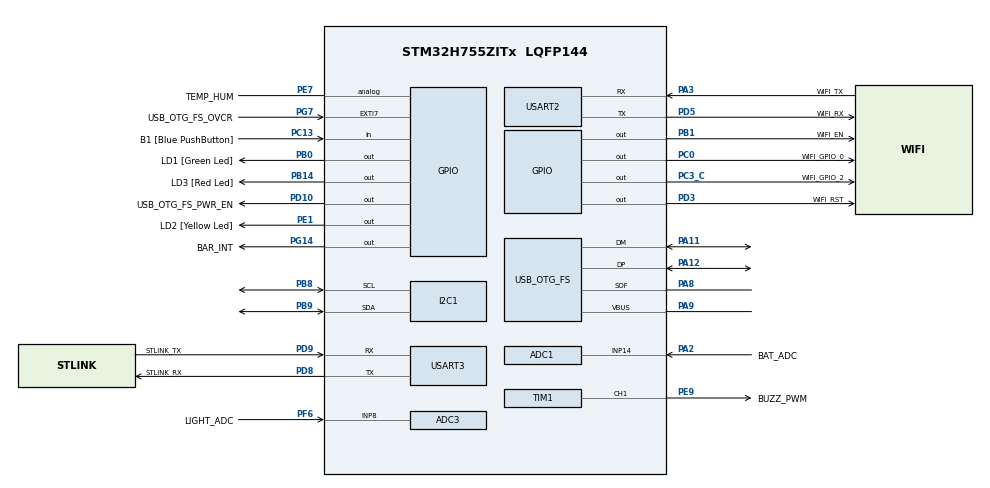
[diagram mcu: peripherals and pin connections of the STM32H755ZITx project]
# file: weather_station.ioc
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ADC1.Channel-1\#ChannelRegularConversion=ADC_CHANNEL_14
ADC1.NbrOfConversionFlag=1
ADC1.OffsetNumber-1\#ChannelRegularConversion=ADC_OFFSET_NONE
ADC1.OffsetSignedSaturation-1\#ChannelRegularConversion=DISABLE
ADC1.Rank-1\#ChannelRegularConversion=1
ADC1.SamplingTime-1\#ChannelRegularConversion=ADC_SAMPLETIME_8CYCLES_5
ADC1.master=1
ADC3.Channel-0\#ChannelRegularConversion=ADC_CHANNEL_8
ADC3.ContinuousConvMode=DISABLE
ADC3.NbrOfConversion=1
ADC3.NbrOfConversionFlag=1
ADC3.OffsetNumber-0\#ChannelRegularConversion=ADC_OFFSET_NONE
ADC3.OffsetSignedSaturation-0\#ChannelRegularConversion=DISABLE
ADC3.Rank-0\#ChannelRegularConversion=1
ADC3.SamplingTime-0\#ChannelRegularConversion=ADC_SAMPLETIME_8CYCLES_5
ARM.CMSIS.5.7.0.CMSISJjCORE=true
ARM.CMSIS.5.7.0.CMSISOoDriverJjI2CJjCustom=true
ARM.CMSIS.5.7.0.CMSISOoDriverJjUSARTJjCustom=true
ARM.CMSIS.5.7.0.CMSISOoDriverJjWiFiJjCustom=true
CortexM4.IPs=FATFS_M4\:I,FREERTOS_M4\:I,IWDG2\:I,RCC,WWDG2\:I,DMA,BDMA,MDMA,NVIC2\:I,USART3,DEBUG,USB_DEVICE_M4\:I,USB_HOST_M4\:I,PDM2PCM_M4\:I,PWR,RESMGR_UTILITY,SYS_M4\:I,CORTEX_M4\:I,OPENAMP_M4\:I,VREFBUF
CortexM7.IPs=FATFS_M7\:I,FREERTOS_M7\:I,IWDG1\:I,RCC\:I,WWDG1\:I,DMA\:I,BDMA\:I,MDMA\:I,NVIC1\:I,USART3\:I,USB_OTG_FS\:I,SYS\:I,CORTEX_M7\:I,DEBUG\:I,USB_DEVICE_M7\:I,USB_HOST_M7\:I,PDM2PCM_M7\:I,PWR\:I,RESMGR_UTILITY\:I,OPENAMP_M7\:I,VREFBUF\:I,ADC3\:I,TIM1\:I,USART2\:I,STMicroelectronics.X-CUBE-ALGOBUILD.1.1.0\:I,I2C1\:I,TIM6\:I,ADC1\:I
CortexM7.Pins=PC13,PC0,PC3_C,PB0,PB1,PE7,PB14,PD10,PD3,PG14,PE1
I2C1.Timing=0x307075B1
Mcu.Family=STM32H7
Mcu.Name=STM32H755ZITx
Mcu.Package=LQFP144
NVIC1.PriorityGroup=NVIC_PRIORITYGROUP_4
NVIC2.PriorityGroup=NVIC_PRIORITYGROUP_4
PA11.Mode=Device_Only
PA11.PinAttribute=CortexM7
PA11.Signal=USB_OTG_FS_DM
PA12.Mode=Device_Only
PA12.PinAttribute=CortexM7
PA12.Signal=USB_OTG_FS_DP
PA2.GPIO_Label=BAT_ADC
PA2.PinAttribute=CortexM7
PA2.Signal=ADCx_INP14
PA3.GPIO_Label=WIFI_TX
PA3.Mode=Asynchronous
PA3.PinAttribute=CortexM7
PA3.Signal=USART2_RX
PA8.Mode=Activate_SOF_FS
PA8.PinAttribute=CortexM7
PA8.Signal=USB_OTG_FS_SOF
PA9.Mode=Activate_VBUS
PA9.PinAttribute=CortexM7
PA9.Signal=USB_OTG_FS_VBUS
PB0.GPIO_Label=LD1 [Green Led]
PB0.PinAttribute=CortexM7
PB0.Signal=GPIO_Output
PB1.GPIO_Label=WIFI_EN
PB1.GPIO_PuPd=GPIO_PULLUP
PB1.PinAttribute=CortexM7
PB1.Signal=GPIO_Output
PB14.GPIO_Label=LD3 [Red Led]
PB14.PinAttribute=CortexM7
PB14.Signal=GPIO_Output
PB8.Mode=I2C
PB8.PinAttribute=CortexM7
PB8.Signal=I2C1_SCL
PB9.Mode=I2C
PB9.PinAttribute=CortexM7
PB9.Signal=I2C1_SDA
PC0.GPIO_Label=WIFI_GPIO_0
PC0.PinAttribute=CortexM7
PC0.Signal=GPIO_Output
PC13.GPIO_Label=B1 [Blue PushButton]
PC13.PinAttribute=CortexM7
PC13.Signal=GPIO_Input
PC14-OSC32_IN\ (OSC32_IN).PinAttribute=CortexM7
PC14-OSC32_IN\ (OSC32_IN).Signal=RCC_OSC32_IN
PC15-OSC32_OUT\ (OSC32_OUT).PinAttribute=CortexM7
PC15-OSC32_OUT\ (OSC32_OUT).Signal=RCC_OSC32_OUT
PC3_C.GPIO_Label=WIFI_GPIO_2
PC3_C.PinAttribute=CortexM7
PC3_C.Signal=GPIO_Output
PD10.GPIO_Label=USB_OTG_FS_PWR_EN
PD10.PinAttribute=CortexM7
PD10.Signal=GPIO_Output
PD3.GPIO_Label=WIFI_RST
PD3.PinAttribute=CortexM7
PD3.Signal=GPIO_Output
PD5.GPIO_Label=WIFI_RX
PD5.Mode=Asynchronous
PD5.PinAttribute=CortexM7
PD5.Signal=USART2_TX
PD8.GPIO_Label=STLINK_RX
PD8.Mode=Asynchronous
PD8.PinAttribute=CortexM7
PD8.Signal=USART3_TX
PD9.GPIO_Label=STLINK_TX
PD9.Mode=Asynchronous
PD9.PinAttribute=CortexM7
PD9.Signal=USART3_RX
PE1.GPIO_Label=LD2 [Yellow Led]
PE1.PinAttribute=CortexM7
PE1.Signal=GPIO_Output
PE7.GPIO_Label=TEMP_HUM
PE7.PinAttribute=CortexM7
PE7.Signal=GPIO_Analog
PE9.GPIO_Label=BUZZ_PWM
PE9.PinAttribute=CortexM7
PE9.Signal=S_TIM1_CH1
PF6.GPIO_Label=LIGHT_ADC
PF6.Mode=IN8-Single-Ended
PF6.PinAttribute=CortexM7
PF6.Signal=ADC3_INP8
PG14.GPIO_Label=BAR_INT
PG14.PinAttribute=CortexM7
PG14.Signal=GPIO_Output
PG7.GPIO_Label=USB_OTG_FS_OVCR
PG7.PinAttribute=Free
PG7.Signal=GPXTI7
PH0-OSC_IN\ (PH0).Mode=HSE-External-Oscillator
PH0-OSC_IN\ (PH0).PinAttribute=CortexM7
PH0-OSC_IN\ (PH0).Signal=RCC_OSC_IN
PH1-OSC_OUT\ (PH1).Mode=HSE-External-Oscillator
PH1-OSC_OUT\ (PH1).PinAttribute=CortexM7
PH1-OSC_OUT\ (PH1).Signal=RCC_OSC_OUT
ProjectManager.HeapSize=0x200
ProjectManager.StackSize=0x400
ProjectManager.TargetToolchain=STM32CubeIDE
RCC.ADCFreq_Value=150000000
RCC.APB1Freq_Value=120000000
RCC.APB2Freq_Value=120000000
RCC.APB3Freq_Value=120000000
RCC.APB4Freq_Value=120000000
RCC.CortexFreq_Value=480000000
RCC.D1PPRE=RCC_APB3_DIV2
RCC.D2PPRE1=RCC_APB1_DIV2
RCC.D2PPRE2=RCC_APB2_DIV2
RCC.D3PPRE=RCC_APB4_DIV2
RCC.DIVM1=1
RCC.DIVM2=1
RCC.DIVN1=120
RCC.DIVN2=18
RCC.DIVP2=1
RCC.DIVQ1=20
RCC.HCLKFreq_Value=240000000
RCC.HPRE=RCC_HCLK_DIV2
RCC.HSE_VALUE=8000000
RCC.PLL2FRACN=6144
RCC.PLL3FRACN=0
RCC.PLLFRACN=0
RCC.SYSCLKFreq_VALUE=480000000
RCC.SYSCLKSource=RCC_SYSCLKSOURCE_PLLCLK
RCC.SupplySource=PWR_DIRECT_SMPS_SUPPLY
RCC.USBFreq_Value=48000000
SH.ADCx_INP14.0=ADC1_INP14,IN14-Single-Ended
SH.S_TIM1_CH1.0=TIM1_CH1,PWM Generation1 CH1
STMicroelectronics.X-CUBE-ALGOBUILD.1.1.0.LibraryCcDSPOoLibraryJjDSPOoLibrary=true
TIM1.Channel-PWM\ Generation1\ CH1=TIM_CHANNEL_1
TIM1.Period=1000-1
TIM1.Prescaler=240-1
TIM6.Period=0xffff
TIM6.Prescaler=239
USART2.VirtualMode-Asynchronous=VM_ASYNC
USART3.VirtualMode-Asynchronous=VM_ASYNC
USB_OTG_FS.VirtualMode=Device_Only
VP_STMicroelectronics.X-CUBE-ALGOBUILD_VS_DSPOoLibraryJjLibrary_1.1.0.Mode=DSPOoLibraryJjLibrary
VP_SYS_M4_VS_Systick.Mode=SysTick
VP_TIM1_VS_ClockSourceINT.Mode=Internal
VP_TIM6_VS_ClockSourceINT.Mode=Enable_Timer
board=NUCLEO-H755ZI-Q

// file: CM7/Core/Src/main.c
/* USER CODE BEGIN Header */
/**
  ******************************************************************************
  * @file           : main.c
  * @brief          : Main program body
  ******************************************************************************
  * @attention
  *
  * <h2><center>&copy; Copyright (c) 2020 STMicroelectronics.
  * All rights reserved.</center></h2>
  *
  * This software component is licensed by ST under BSD 3-Clause license,
  * the "License"; You may not use this file except in compliance with the
  * License. You may obtain a copy of the License at:
  *                        opensource.org/licenses/BSD-3-Clause
  *
  ******************************************************************************
  */
/* USER CODE END Header */
#include "main.h"
#include "adc.h"
#include "i2c.h"
#include "tim.h"
#include "usart.h"
#include "usb_otg.h"
#include "gpio.h"

/* USER CODE BEGIN PD */
#define HSEM_ID_0 (0U) /* HW semaphore 0*/
/* USER CODE END PD */

void SystemClock_Config(void);

int main(void)
{

/* USER CODE BEGIN Boot_Mode_Sequence_0 */
  int32_t timeout;
/* USER CODE END Boot_Mode_Sequence_0 */

/* USER CODE BEGIN Boot_Mode_Sequence_1 */
  /* Wait until CPU2 boots and enters in stop mode or timeout*/
  timeout = 0xFFFF;
  while((__HAL_RCC_GET_FLAG(RCC_FLAG_D2CKRDY) != RESET) && (timeout-- > 0));
  if ( timeout < 0 )
  {
  Error_Handler();
  }
/* USER CODE END Boot_Mode_Sequence_1 */
  /* MCU Configuration--------------------------------------------------------*/

  /* Reset of all peripherals, Initializes the Flash interface and the Systick. */
  HAL_Init();

  /* USER CODE BEGIN Init */
  char test[28];
  double temp_hum_sens[2] = {0, 0}, light_level = 0;
  /* USER CODE END Init */

  /* Configure the system clock */
  SystemClock_Config();
/* USER CODE BEGIN Boot_Mode_Sequence_2 */
/* When system initialization is finished, Cortex-M7 will release Cortex-M4 by means of
HSEM notification */
/*HW semaphore Clock enable*/
__HAL_RCC_HSEM_CLK_ENABLE();
/*Take HSEM */
HAL_HSEM_FastTake(HSEM_ID_0);
/*Release HSEM in order to notify the CPU2(CM4)*/
HAL_HSEM_Release(HSEM_ID_0,0);
/* wait until CPU2 wakes up from stop mode */
timeout = 0xFFFF;
while((__HAL_RCC_GET_FLAG(RCC_FLAG_D2CKRDY) == RESET) && (timeout-- > 0));
if ( timeout < 0 )
{
Error_Handler();
}
/* USER CODE END Boot_Mode_Sequence_2 */

  /* Initialize all configured peripherals */
  MX_GPIO_Init();
  MX_USART3_UART_Init();
  MX_USB_OTG_FS_PCD_Init();
  MX_ADC3_Init();
  MX_TIM1_Init();
  MX_USART2_UART_Init();
  MX_I2C1_Init();
  MX_TIM6_Init();
  MX_ADC1_Init();

  /* Infinite loop */
  /* USER CODE BEGIN WHILE */
  while (1){
	  light_level = analog_sensor(&hadc3, 800);
	  battery_level(&hadc1, test, 3.7);
	  dht11_run(htim6, TEMP_HUM_GPIO_Port, TEMP_HUM_Pin, temp_hum_sens);

    /* USER CODE END WHILE */

  }
}

void SystemClock_Config(void)
{
  RCC_OscInitTypeDef RCC_OscInitStruct = {0};
  RCC_ClkInitTypeDef RCC_ClkInitStruct = {0};
  RCC_PeriphCLKInitTypeDef PeriphClkInitStruct = {0};

  /** Supply configuration update enable
  */
  HAL_PWREx_ConfigSupply(PWR_DIRECT_SMPS_SUPPLY);
  /** Configure the main internal regulator output voltage
  */
  __HAL_PWR_VOLTAGESCALING_CONFIG(PWR_REGULATOR_VOLTAGE_SCALE0);

  while(!__HAL_PWR_GET_FLAG(PWR_FLAG_VOSRDY)) {}
  /** Macro to configure the PLL clock source
  */
  __HAL_RCC_PLL_PLLSOURCE_CONFIG(RCC_PLLSOURCE_HSE);
  /** Initializes the RCC Oscillators according to the specified parameters
  * in the RCC_OscInitTypeDef structure.
  */
  RCC_OscInitStruct.OscillatorType = RCC_OSCILLATORTYPE_HSE;
  RCC_OscInitStruct.HSEState = RCC_HSE_ON;
  RCC_OscInitStruct.PLL.PLLState = RCC_PLL_ON;
  RCC_OscInitStruct.PLL.PLLSource = RCC_PLLSOURCE_HSE;
  RCC_OscInitStruct.PLL.PLLM = 1;
  RCC_OscInitStruct.PLL.PLLN = 120;
  RCC_OscInitStruct.PLL.PLLP = 2;
  RCC_OscInitStruct.PLL.PLLQ = 20;
  RCC_OscInitStruct.PLL.PLLR = 2;
  RCC_OscInitStruct.PLL.PLLRGE = RCC_PLL1VCIRANGE_3;
  RCC_OscInitStruct.PLL.PLLVCOSEL = RCC_PLL1VCOWIDE;
  RCC_OscInitStruct.PLL.PLLFRACN = 0;
  if (HAL_RCC_OscConfig(&RCC_OscInitStruct) != HAL_OK)
  {
    Error_Handler();
  }
  /** Initializes the CPU, AHB and APB buses clocks
  */
  RCC_ClkInitStruct.ClockType = RCC_CLOCKTYPE_HCLK|RCC_CLOCKTYPE_SYSCLK
                              |RCC_CLOCKTYPE_PCLK1|RCC_CLOCKTYPE_PCLK2
                              |RCC_CLOCKTYPE_D3PCLK1|RCC_CLOCKTYPE_D1PCLK1;
  RCC_ClkInitStruct.SYSCLKSource = RCC_SYSCLKSOURCE_PLLCLK;
  RCC_ClkInitStruct.SYSCLKDivider = RCC_SYSCLK_DIV1;
  RCC_ClkInitStruct.AHBCLKDivider = RCC_HCLK_DIV2;
  RCC_ClkInitStruct.APB3CLKDivider = RCC_APB3_DIV2;
  RCC_ClkInitStruct.APB1CLKDivider = RCC_APB1_DIV2;
  RCC_ClkInitStruct.APB2CLKDivider = RCC_APB2_DIV2;
  RCC_ClkInitStruct.APB4CLKDivider = RCC_APB4_DIV2;

  if (HAL_RCC_ClockConfig(&RCC_ClkInitStruct, FLASH_LATENCY_4) != HAL_OK)
  {
    Error_Handler();
  }
  PeriphClkInitStruct.PeriphClockSelection = RCC_PERIPHCLK_USART3|RCC_PERIPHCLK_USART2
                              |RCC_PERIPHCLK_ADC|RCC_PERIPHCLK_I2C1
                              |RCC_PERIPHCLK_USB;
  PeriphClkInitStruct.PLL2.PLL2M = 1;
  PeriphClkInitStruct.PLL2.PLL2N = 18;
  PeriphClkInitStruct.PLL2.PLL2P = 1;
  PeriphClkInitStruct.PLL2.PLL2Q = 2;
  PeriphClkInitStruct.PLL2.PLL2R = 2;
  PeriphClkInitStruct.PLL2.PLL2RGE = RCC_PLL2VCIRANGE_3;
  PeriphClkInitStruct.PLL2.PLL2VCOSEL = RCC_PLL2VCOMEDIUM;
  PeriphClkInitStruct.PLL2.PLL2FRACN = 6144;
  PeriphClkInitStruct.Usart234578ClockSelection = RCC_USART234578CLKSOURCE_D2PCLK1;
  PeriphClkInitStruct.I2c123ClockSelection = RCC_I2C123CLKSOURCE_D2PCLK1;
  PeriphClkInitStruct.UsbClockSelection = RCC_USBCLKSOURCE_PLL;
  PeriphClkInitStruct.AdcClockSelection = RCC_ADCCLKSOURCE_PLL2;
  if (HAL_RCCEx_PeriphCLKConfig(&PeriphClkInitStruct) != HAL_OK)
  {
    Error_Handler();
  }
  /** Enable USB Voltage detector
  */
  HAL_PWREx_EnableUSBVoltageDetector();
}

void Error_Handler(void)
{
}

/************************ (C) COPYRIGHT STMicroelectronics *****END OF FILE****/
